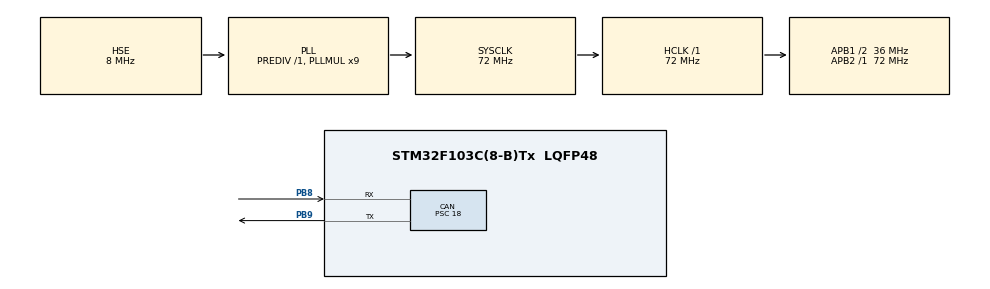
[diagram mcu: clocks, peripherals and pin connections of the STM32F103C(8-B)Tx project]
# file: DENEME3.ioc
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CAN.BS1=CAN_BS1_2TQ
CAN.CalculateBaudRate=500000
CAN.CalculateTimeBit=2000
CAN.CalculateTimeQuantum=500.0
CAN.Mode=CAN_MODE_LOOPBACK
CAN.Prescaler=18
Mcu.Family=STM32F1
Mcu.Name=STM32F103C(8-B)Tx
Mcu.Package=LQFP48
NVIC.CAN1_RX1_IRQn=true\:0\:0\:false\:false\:true\:true\:true\:true
NVIC.PriorityGroup=NVIC_PRIORITYGROUP_4
NVIC.USB_LP_CAN1_RX0_IRQn=true\:0\:0\:false\:false\:true\:true\:true\:true
PA13.Mode=Serial_Wire
PA13.Signal=SYS_JTMS-SWDIO
PA14.Mode=Serial_Wire
PA14.Signal=SYS_JTCK-SWCLK
PB8.Mode=CAN_Activate
PB8.Signal=CAN_RX
PB9.Mode=CAN_Activate
PB9.Signal=CAN_TX
PD0-OSC_IN.Mode=HSE-External-Oscillator
PD0-OSC_IN.Signal=RCC_OSC_IN
PD1-OSC_OUT.Mode=HSE-External-Oscillator
PD1-OSC_OUT.Signal=RCC_OSC_OUT
ProjectManager.HeapSize=0x200
ProjectManager.StackSize=0x400
ProjectManager.TargetToolchain=STM32CubeIDE
RCC.AHBFreq_Value=72000000
RCC.APB1CLKDivider=RCC_HCLK_DIV2
RCC.APB1Freq_Value=36000000
RCC.APB1TimFreq_Value=72000000
RCC.APB2Freq_Value=72000000
RCC.APB2TimFreq_Value=72000000
RCC.HCLKFreq_Value=72000000
RCC.PLLMUL=RCC_PLL_MUL9
RCC.PLLSourceVirtual=RCC_PLLSOURCE_HSE
RCC.SYSCLKFreq_VALUE=72000000
RCC.SYSCLKSource=RCC_SYSCLKSOURCE_PLLCLK
RCC.USBFreq_Value=72000000
board=custom

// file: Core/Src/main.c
/* USER CODE BEGIN Header */
/**
  ******************************************************************************
  * @file           : main.c
  * @brief          : Main program body
  ******************************************************************************
  * @attention
  *
  * Copyright (c) 2023 STMicroelectronics.
  * All rights reserved.
  *
  * This software is licensed under terms that can be found in the LICENSE file
  * in the root directory of this software component.
  * If no LICENSE file comes with this software, it is provided AS-IS.
  *
  ******************************************************************************
  */
/* USER CODE END Header */
#include "main.h"

CAN_HandleTypeDef hcan;

/* USER CODE BEGIN PV */
int basarili=0;
/* USER CODE END PV */

void SystemClock_Config(void);
static void MX_GPIO_Init(void);
static void MX_CAN_Init(void);

/* USER CODE BEGIN 0 */
CAN_HandleTypeDef hcan;
CAN_TxHeaderTypeDef TXHeader;
CAN_RxHeaderTypeDef RXHeader;

    uint32_t TxMailbox;
 	uint8_t message[8];
 	uint8_t rxmessage[8]={0,0,0,0,0,0,0,0};
 	uint8_t count=0;

 	void HAL_CAN_RxFifo0MsgPendingCallback(CAN_HandleTypeDef *hcan){
 		HAL_CAN_GetRxMessage(hcan, CAN_RX_FIFO0, &RXHeader, rxmessage);
 	count++;
 	}

/* USER CODE END 0 */

int main(void)
{

  /* MCU Configuration--------------------------------------------------------*/

  /* Reset of all peripherals, Initializes the Flash interface and the Systick. */
  HAL_Init();

  /* Configure the system clock */
  SystemClock_Config();

  /* Initialize all configured peripherals */
  MX_GPIO_Init();
  MX_CAN_Init();
  /* USER CODE BEGIN 2 */

HAL_CAN_Start(&hcan);
HAL_CAN_ActivateNotification(&hcan,CAN_IT_RX_FIFO0_MSG_PENDING);

    TXHeader.DLC=8; //how many bites we send
    TXHeader.ExtId=0;
  	TXHeader.IDE=CAN_ID_STD; //STANDART MI EXTENDED Mİ
  	TXHeader.StdId=0x65; //adress
  	TXHeader.RTR=CAN_RTR_DATA; //data frame
    TXHeader.TransmitGlobalTime=DISABLE;

  /* USER CODE END 2 */

  /* Infinite loop */
  /* USER CODE BEGIN WHILE */
  while (1)
  {
 message[]={0x01,0x02,0x03,0x04,0x05,0x06,0x07,0x08};
    HAL_CAN_AddTxMessage(&hcan,&TXHeader,message,&TxMailbox);
   HAL_Delay(500);
    /* USER CODE END WHILE */

  }
}

void SystemClock_Config(void)
{
  RCC_OscInitTypeDef RCC_OscInitStruct = {0};
  RCC_ClkInitTypeDef RCC_ClkInitStruct = {0};

  /** Initializes the RCC Oscillators according to the specified parameters
  * in the RCC_OscInitTypeDef structure.
  */
  RCC_OscInitStruct.OscillatorType = RCC_OSCILLATORTYPE_HSE;
  RCC_OscInitStruct.HSEState = RCC_HSE_ON;
  RCC_OscInitStruct.HSEPredivValue = RCC_HSE_PREDIV_DIV1;
  RCC_OscInitStruct.HSIState = RCC_HSI_ON;
  RCC_OscInitStruct.PLL.PLLState = RCC_PLL_ON;
  RCC_OscInitStruct.PLL.PLLSource = RCC_PLLSOURCE_HSE;
  RCC_OscInitStruct.PLL.PLLMUL = RCC_PLL_MUL9;
  if (HAL_RCC_OscConfig(&RCC_OscInitStruct) != HAL_OK)
  {
    Error_Handler();
  }

  /** Initializes the CPU, AHB and APB buses clocks
  */
  RCC_ClkInitStruct.ClockType = RCC_CLOCKTYPE_HCLK|RCC_CLOCKTYPE_SYSCLK
                              |RCC_CLOCKTYPE_PCLK1|RCC_CLOCKTYPE_PCLK2;
  RCC_ClkInitStruct.SYSCLKSource = RCC_SYSCLKSOURCE_PLLCLK;
  RCC_ClkInitStruct.AHBCLKDivider = RCC_SYSCLK_DIV1;
  RCC_ClkInitStruct.APB1CLKDivider = RCC_HCLK_DIV2;
  RCC_ClkInitStruct.APB2CLKDivider = RCC_HCLK_DIV1;

  if (HAL_RCC_ClockConfig(&RCC_ClkInitStruct, FLASH_LATENCY_2) != HAL_OK)
  {
    Error_Handler();
  }
}

static void MX_CAN_Init(void)
{

  hcan.Instance = CAN1;
  hcan.Init.Prescaler = 18;
  hcan.Init.Mode = CAN_MODE_LOOPBACK;
  hcan.Init.SyncJumpWidth = CAN_SJW_1TQ;
  hcan.Init.TimeSeg1 = CAN_BS1_2TQ;
  hcan.Init.TimeSeg2 = CAN_BS2_1TQ;
  hcan.Init.TimeTriggeredMode = DISABLE;
  hcan.Init.AutoBusOff = DISABLE;
  hcan.Init.AutoWakeUp = DISABLE;
  hcan.Init.AutoRetransmission = DISABLE;
  hcan.Init.ReceiveFifoLocked = DISABLE;
  hcan.Init.TransmitFifoPriority = DISABLE;
  if (HAL_CAN_Init(&hcan) != HAL_OK)
  {
    Error_Handler();
  }
  /* USER CODE BEGIN CAN_Init 2 */
  CAN_FilterTypeDef filterconf;

  filterconf.FilterActivation=ENABLE;
  filterconf.FilterBank=10;
  filterconf.FilterFIFOAssignment=CAN_FILTER_FIFO0;
  filterconf.FilterIdHigh=0;
  filterconf.FilterIdLow=0x0000;
  filterconf.FilterMaskIdHigh=0;
  filterconf.FilterMaskIdLow=0x0000;
  filterconf.FilterMode=CAN_FILTERMODE_IDMASK ;
  filterconf.FilterScale=CAN_FILTERSCALE_32BIT;
  filterconf.SlaveStartFilterBank=0;

  HAL_CAN_ConfigFilter(&hcan, &filterconf);
  /* USER CODE END CAN_Init 2 */

}

static void MX_GPIO_Init(void)
{

  /* GPIO Ports Clock Enable */
  __HAL_RCC_GPIOD_CLK_ENABLE();
  __HAL_RCC_GPIOA_CLK_ENABLE();
  __HAL_RCC_GPIOB_CLK_ENABLE();

}

void Error_Handler(void)
{
  __disable_irq();
  while (1)
  {
  }
}
